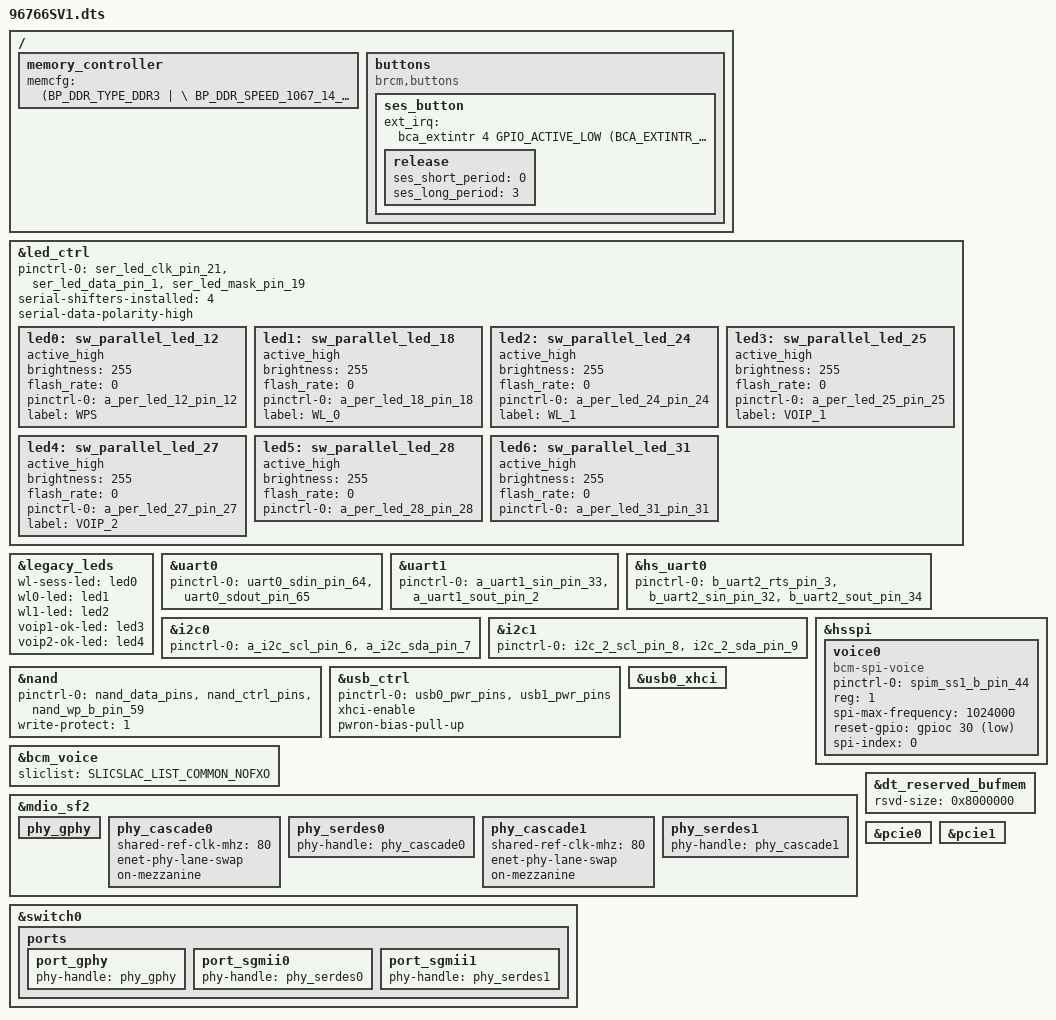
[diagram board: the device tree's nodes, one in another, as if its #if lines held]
#include "6766.dtsi"
#include "../bcm_voice.dtsi"

/ {
	memory_controller {
		memcfg = <(BP_DDR_TYPE_DDR3       | \
			BP_DDR_SPEED_1067_14_14_14    | \
			BP_DDR_TOTAL_SIZE_512MB      | \
			BP_DDR_DEVICE_WIDTH_16        | \
			BP_DDR_TOTAL_WIDTH_16BIT      | \
			BP_DDR_6766_DEFAULT           | \
			BP_DDR_CONFIG_DEBUG)>;
	};

	buttons {
		compatible = "brcm,buttons";
		ses_button {
			ext_irq = <&bca_extintr 4 GPIO_ACTIVE_LOW (BCA_EXTINTR_TYPE_LOW_LEVEL | BCA_EXTINTR_TYPE_SENSE_EDGE)>;
			release {
				ses_short_period = <0>;
				ses_long_period = <3>;
			};
		};
	};
};

&led_ctrl {
	pinctrl-names = "default";
	pinctrl-0 = <&ser_led_clk_pin_21 &ser_led_data_pin_1 &ser_led_mask_pin_19>;
	serial-shifters-installed = <4>;
	serial-data-polarity-high;

	led0: sw_parallel_led_12 {
		active_high;
		brightness = <255>;
		flash_rate = <0>;
		status = "okay";
		pinctrl-0 = <&a_per_led_12_pin_12>;
		label = "WPS";
	};

	led1: sw_parallel_led_18 {
		active_high;
		brightness = <255>;
		flash_rate = <0>;
		pinctrl-0 = <&a_per_led_18_pin_18>;
		status = "okay";
		label = "WL_0";
	};

	led2: sw_parallel_led_24 {
		active_high;
		brightness = <255>;
		flash_rate = <0>;
		pinctrl-0 = <&a_per_led_24_pin_24>;
		status = "okay";
		label = "WL_1";
	};

	led3: sw_parallel_led_25 {
		active_high;
		brightness = <255>;
		flash_rate = <0>;
		pinctrl-0 = <&a_per_led_25_pin_25>;
		status = "okay";
		label = "VOIP_1";
	};

	led4: sw_parallel_led_27 {
		active_high;
		brightness = <255>;
		flash_rate = <0>;
		pinctrl-0 = <&a_per_led_27_pin_27>;
		status = "okay";
		label = "VOIP_2";
	};

	led5: sw_parallel_led_28 {
		active_high;
		brightness = <255>;
		flash_rate = <0>;
		pinctrl-0 = <&a_per_led_28_pin_28>;
		status = "okay";
	};

	led6: sw_parallel_led_31 {
		active_high;
		brightness = <255>;
		flash_rate = <0>;
		pinctrl-0 = <&a_per_led_31_pin_31>;
		status = "okay";
	};
};

&legacy_leds {
	wl-sess-led = <&led0>;
	wl0-led = <&led1>;
	wl1-led = <&led2>;
	voip1-ok-led = <&led3>;
	voip2-ok-led = <&led4>;
};

&uart0 {
	pinctrl-names = "default";
	pinctrl-0 = <&uart0_sdin_pin_64 &uart0_sdout_pin_65>;
	status = "okay";
};

&uart1 {
	pinctrl-names = "default";
	pinctrl-0 = <&a_uart1_sin_pin_33 &a_uart1_sout_pin_2>;
	status = "okay";
};

&hs_uart0 {
	pinctrl-0 = <&b_uart2_rts_pin_3 &b_uart2_sin_pin_32 &b_uart2_sout_pin_34>;
	/* b_uart2_cts_pin_44 shared with SPI slave */
	pinctrl-names = "default";
	status = "okay";
};

&i2c0 {
	pinctrl-names = "default";
	pinctrl-0 = <&a_i2c_scl_pin_6 &a_i2c_sda_pin_7>;
	status = "okay";
};

&i2c1 {
	pinctrl-names = "default";
	pinctrl-0 = <&i2c_2_scl_pin_8 &i2c_2_sda_pin_9>;
	status = "okay";
};

&hsspi {
	status = "okay";
	voice0 {
		pinctrl-0 = <&spim_ss1_b_pin_44>;
		pinctrl-names = "default";
		compatible = "bcm-spi-voice";
		reg = <1>; /* chip select 1 */
		spi-max-frequency = <1024000>;
		reset-gpio = <&gpioc 30 GPIO_ACTIVE_LOW>;
		spi-index = <0>;/* voice header index */
	};
};

&nand {
	pinctrl-0 = <&nand_data_pins &nand_ctrl_pins &nand_wp_b_pin_59>;
	write-protect = <1>;
	status = "okay";
};

&usb_ctrl {
    pinctrl-names="default";
    pinctrl-0 = <&usb0_pwr_pins &usb1_pwr_pins>;
    status = "okay";
    xhci-enable;
    pwron-bias-pull-up;
};

&usb0_xhci {
    status = "okay";
};

&bcm_voice {
	sliclist = SLICSLAC_LIST_COMMON_NOFXO;
};

&mdio_sf2 {
	/* Port PHY mapping:
	        port_imp -8#0- port_gphy <----> phy_gphy
	                  # 5- port_sgmii0 <--> phy_serdes0 - phy_cascade0
	                  ##6- port_sgmii1 <--> phy_serdes1 - phy_cascade1
	 */
	phy_gphy {
		status = "okay";
	};
	phy_cascade0 {
		shared-ref-clk-mhz = <80>;
		enet-phy-lane-swap;
		status = "okay";
		on-mezzanine;
	};
	phy_serdes0 {
		phy-handle = <&phy_cascade0>;
		status = "okay";
	};
	phy_cascade1 {
		shared-ref-clk-mhz = <80>;
		enet-phy-lane-swap;
		status = "okay";
		on-mezzanine;
	};
	phy_serdes1 {
		phy-handle = <&phy_cascade1>;
		status = "okay";
	};
};

&switch0 {

	ports {
		port_gphy {
			phy-handle = <&phy_gphy>;
			status = "okay";
		};
		port_sgmii0 {
			phy-handle = <&phy_serdes0>;
			status = "okay";
		};
		port_sgmii1 {
			phy-handle = <&phy_serdes1>;
			status = "okay";
		};
	};
};

#if defined(CONFIG_BCM_MPM) || defined(CONFIG_BCM_MPM_MODULE)
&dt_reserved_bufmem {
	rsvd-size = <0x8000000>;
};
#endif

#if defined(CONFIG_BCM_PCIE_HCD) || defined(CONFIG_BCM_PCIE_HCD_MODULE)
/**********************************************************************/
/* GPIO: Add one define per GPIO (individual or shared) regulator     */
/*       - Skip if no GPIO regulators in use                          */
/**********************************************************************/

/**********************************************************************/
/* Shared: Add brcm,supply-names = "vreg-pcieX" for shared PCIe nodes */
/*         - Skip if not using shared GPIO regulators                 */
/**********************************************************************/

/**********************************************************************/
/* PCIe: Add status = "okay" for each PCIe slots of this boiard       */
/*       - Skip if this is a derivative board (already done in base)  */
/**********************************************************************/
&pcie0 {
	status = "okay";
};

&pcie1 {
	status = "okay";
};
#endif //#if defined(CONFIG_BCM_PCIE_HCD) || defined(CONFIG_BCM_PCIE_HCD_MODULE)
